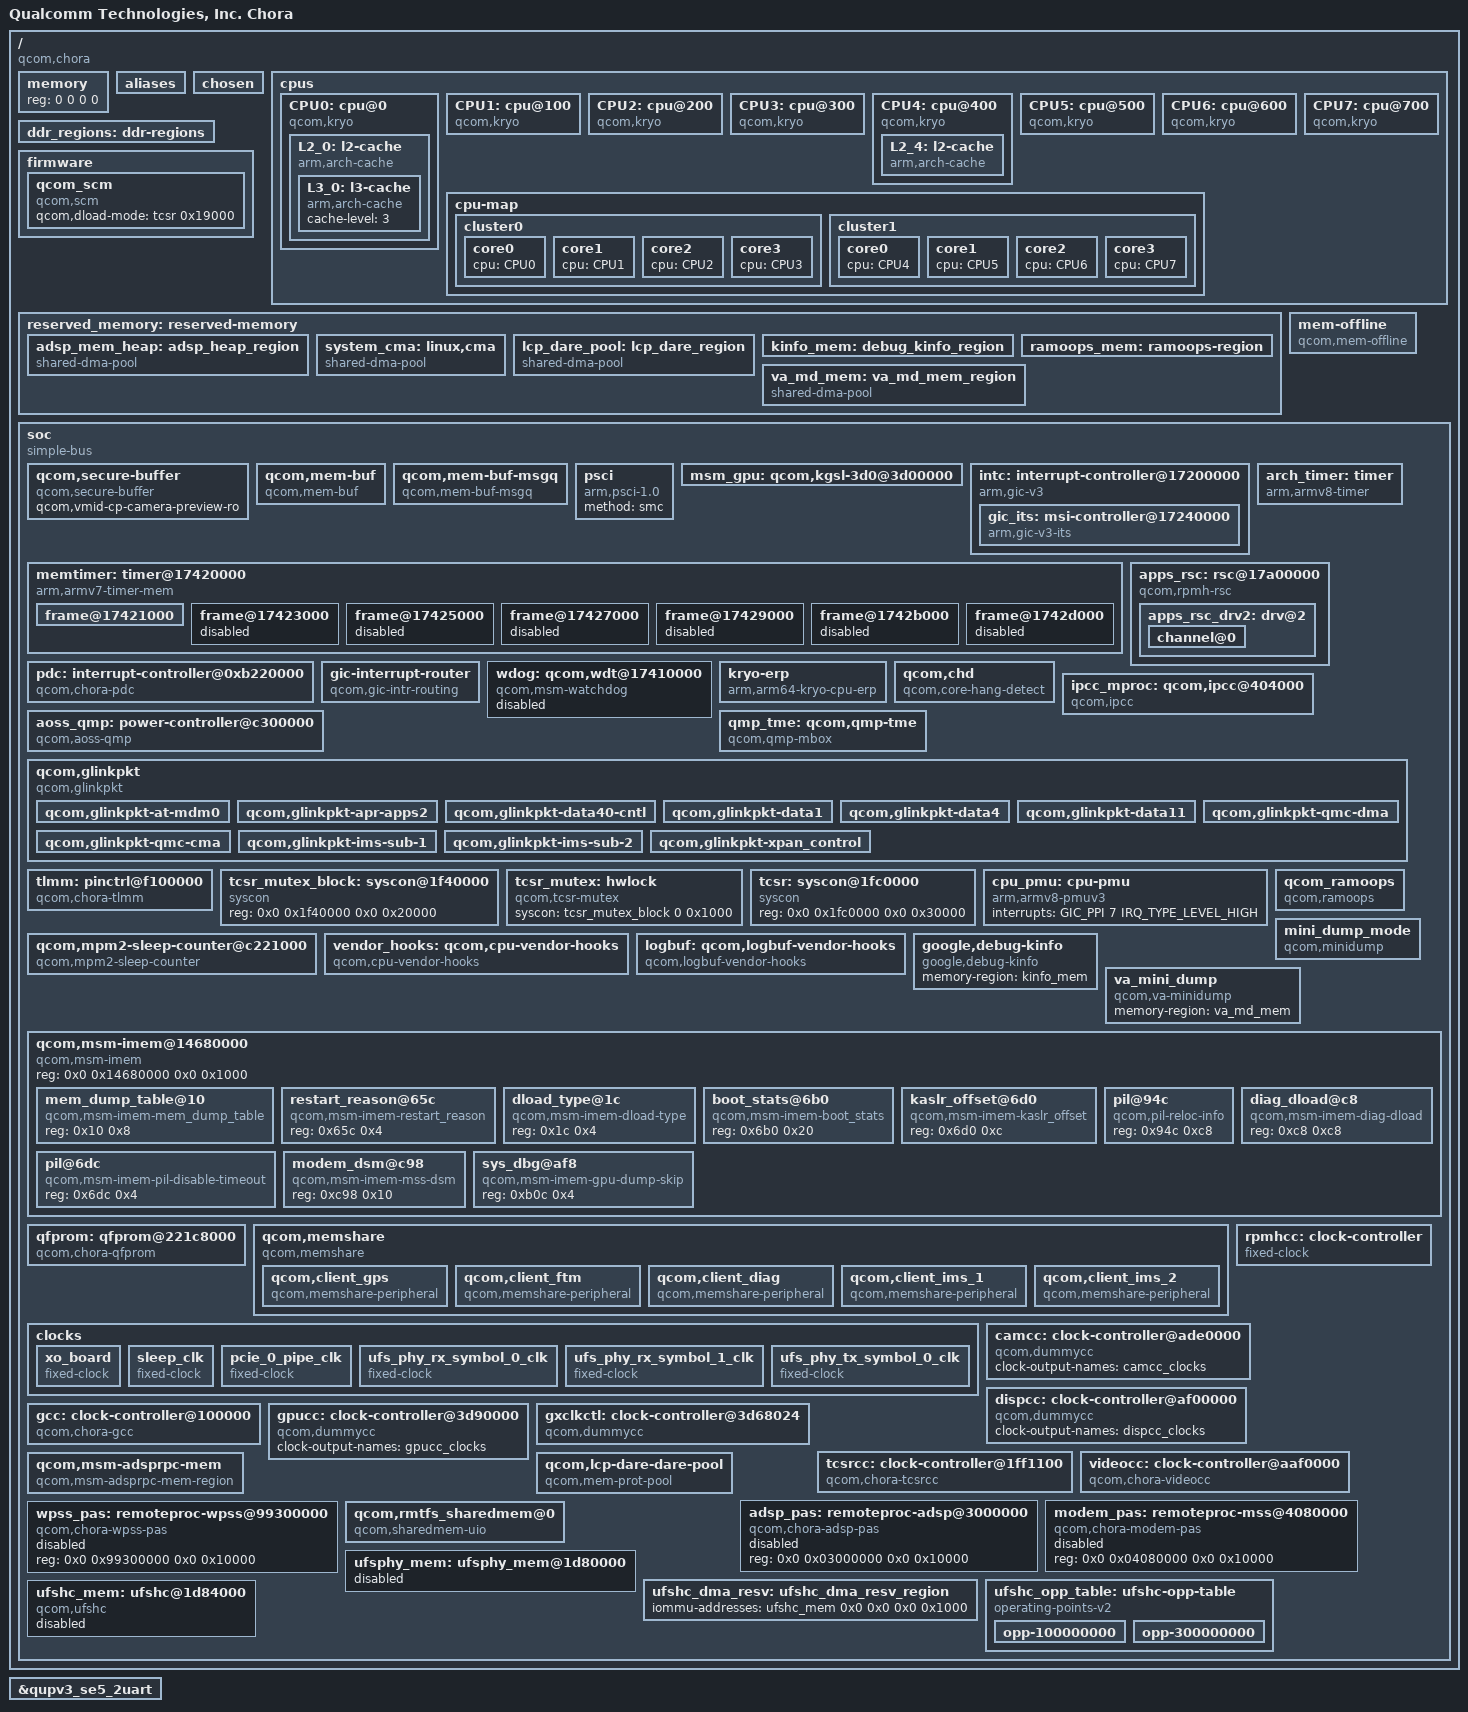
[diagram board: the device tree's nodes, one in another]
// SPDX-License-Identifier: BSD-3-Clause
/*
 * Copyright (c) Qualcomm Technologies, Inc. and/or its subsidiaries.
 */

#include <dt-bindings/clock/qcom,chora-camcc.h>
#include <dt-bindings/clock/qcom,chora-dispcc.h>
#include <dt-bindings/clock/qcom,chora-gcc.h>
#include <dt-bindings/clock/qcom,chora-gpucc.h>
#include <dt-bindings/clock/qcom,chora-tcsrcc.h>
#include <dt-bindings/clock/qcom,chora-videocc.h>
#include <dt-bindings/clock/qcom,rpmh.h>
#include <dt-bindings/interrupt-controller/arm-gic.h>
#include <dt-bindings/soc/qcom,ipcc.h>
#include <dt-bindings/mailbox/qcom-ipcc-canoe.h>
#include <dt-bindings/gpio/gpio.h>
#include <dt-bindings/soc/qcom,rpmh-rsc.h>

/ {
	model = "Qualcomm Technologies, Inc. Chora";
	compatible = "qcom,chora";
	qcom,msm-id = <724 0x10000>;
	interrupt-parent = <&intc>;

	#address-cells = <2>;
	#size-cells = <2>;
	memory { device_type = "memory"; reg = <0 0 0 0>; };

	aliases {
		serial0 = &qupv3_se5_2uart;
		ufshc1 = &ufshc_mem; /* Embedded UFS Slot */
	};

	chosen: chosen {
		bootargs = "loglevel=6 log_buf_len=512K earlycon arm64.nosme arm64.nomte cpufreq.default_governor=performance no-steal-acc kpti=0 swiotlb=0 loop.max_part=7 irqaffinity=0-4 fw_devlink.strict=1 kasan=off rcupdate.rcu_expedited=1 rcu_nocbs=0-7 cgroup_disable=pressure cgroup.memory=nokmem,nosocket disable_dma32=on page_poison=on printk.console_no_auto_verbose=1 sysctl.kernel.panic_on_rcu_stall=1 ftrace_dump_on_oops restrict_cma_redirect=false slub_debug=-";
		stdout-path = "serial0:115200n8";
	};

	cpus {
		#address-cells = <2>;
		#size-cells = <0>;

		CPU0: cpu@0 {
			device_type = "cpu";
			compatible = "qcom,kryo";
			reg = <0x0 0x0>;
			enable-method = "psci";
			next-level-cache = <&L2_0>;
			capacity-dmips-mhz = <1024>;
			dynamic-power-coefficient = <100>;

			L2_0: l2-cache {
				compatible = "arm,arch-cache";
				cache-level = <2>;
				next-level-cache = <&L3_0>;

				L3_0: l3-cache {
					compatible = "arm,arch-cache";
					cache-level = <3>;
				};
			};
		};

		CPU1: cpu@100 {
			device_type = "cpu";
			compatible = "qcom,kryo";
			reg = <0x0 0x100>;
			enable-method = "psci";
			next-level-cache = <&L2_0>;
			capacity-dmips-mhz = <1024>;
			dynamic-power-coefficient = <100>;
		};

		CPU2: cpu@200 {
			device_type = "cpu";
			compatible = "qcom,kryo";
			reg = <0x0 0x200>;
			enable-method = "psci";
			next-level-cache = <&L2_0>;
			capacity-dmips-mhz = <1024>;
			dynamic-power-coefficient = <100>;
		};

		CPU3: cpu@300 {
			device_type = "cpu";
			compatible = "qcom,kryo";
			reg = <0x0 0x300>;
			enable-method = "psci";
			next-level-cache = <&L2_0>;
			capacity-dmips-mhz = <1024>;
			dynamic-power-coefficient = <100>;
		};

		CPU4: cpu@400 {
			device_type = "cpu";
			compatible = "qcom,kryo";
			reg = <0x0 0x400>;
			enable-method = "psci";
			next-level-cache = <&L2_4>;
			capacity-dmips-mhz = <1864>;
			dynamic-power-coefficient = <471>;

			L2_4: l2-cache {
				compatible = "arm,arch-cache";
				cache-level = <2>;
				next-level-cache = <&L3_0>;
			};
		};

		CPU5: cpu@500 {
			device_type = "cpu";
			compatible = "qcom,kryo";
			reg = <0x0 0x500>;
			enable-method = "psci";
			next-level-cache = <&L2_4>;
			capacity-dmips-mhz = <1864>;
			dynamic-power-coefficient = <471>;
		};

		CPU6: cpu@600 {
			device_type = "cpu";
			compatible = "qcom,kryo";
			reg = <0x0 0x600>;
			enable-method = "psci";
			next-level-cache = <&L2_4>;
			capacity-dmips-mhz = <1864>;
			dynamic-power-coefficient = <471>;
		};

		CPU7: cpu@700 {
			device_type = "cpu";
			compatible = "qcom,kryo";
			reg = <0x0 0x700>;
			enable-method = "psci";
			next-level-cache = <&L2_4>;
			capacity-dmips-mhz = <1864>;
			dynamic-power-coefficient = <471>;
		};

		cpu-map {

			cluster0 {

				core0 {
					cpu = <&CPU0>;
				};

				core1 {
					cpu = <&CPU1>;
				};

				core2 {
					cpu = <&CPU2>;
				};

				core3 {
					cpu = <&CPU3>;
				};
			};

			cluster1 {

				core0 {
					cpu = <&CPU4>;
				};

				core1 {
					cpu = <&CPU5>;
				};

				core2 {
					cpu = <&CPU6>;
				};

				core3 {
					cpu = <&CPU7>;
				};
			};
		};
	};

	ddr_regions: ddr-regions { };

	firmware: firmware { };

	reserved_memory: reserved-memory { };

	mem-offline {
		compatible = "qcom,mem-offline";
		offline-sizes = <0x2 0xc0000000 0x1 0x0>;
		granule = <512>;
		qcom,qmp = <&aoss_qmp>;
	};

	soc: soc { };
};

&firmware {
	qcom_scm: qcom_scm {
		compatible = "qcom,scm";
		qcom,dload-mode = <&tcsr 0x19000>;
	};
};

#include "chora-reserved-memory.dtsi"
#include "msm-arm-smmu-chora.dtsi"
#include "chora-dma-heaps.dtsi"

&reserved_memory {
	#address-cells = <2>;
	#size-cells = <2>;
	ranges;

	adsp_mem_heap: adsp_heap_region {
		compatible = "shared-dma-pool";
		alloc-ranges = <0x0 0x00000000 0x0 0xffffffff>;
		reusable;
		alignment = <0x0 0x400000>;
		size = <0x0 0xC00000>;
	};

	/* global autoconfigured region for contiguous allocations */
	system_cma: linux,cma {
		compatible = "shared-dma-pool";
		alloc-ranges = <0x0 0x00000000 0x0 0xffffffff>;
		reusable;
		alignment = <0x0 0x400000>;
		size = <0x0 0x2400000>;
		linux,cma-default;
	};

	lcp_dare_pool: lcp_dare_region {
		compatible = "shared-dma-pool";
		reg = <0x8 0x80000000 0x0 0x6000000>;
		reusable;
		alignment = <0x0 0x400000>;
	};

	kinfo_mem: debug_kinfo_region {
		alloc-ranges = <0x0 0x00000000 0xffffffff 0xffffffff>;
		size = <0x0 0x1000>;
		no-map;
	};

	ramoops_mem: ramoops-region {
		alloc-ranges = <0x1 0x00000000 0xfffffffe 0xffffffff>;
		size = <0x0 0x200000>;
		no-map;
	};

	va_md_mem: va_md_mem_region {
		compatible = "shared-dma-pool";
		alloc-ranges = <0x0 0x00000000 0x0 0xffffffff>;
		reusable;
		size = <0 0x1000000>;
	};
};

&soc {
	#address-cells = <2>;
	#size-cells = <2>;
	ranges = <0 0 0 0 0x10 0>;
	compatible = "simple-bus";

	qcom,secure-buffer {
		compatible = "qcom,secure-buffer";
		qcom,vmid-cp-camera-preview-ro;
	};

	qcom,mem-buf {
		compatible = "qcom,mem-buf";
		qcom,mem-buf-capabilities = "supplier";
		qcom,vmid = <3>;
	};

	qcom,mem-buf-msgq {
		compatible = "qcom,mem-buf-msgq";
	};

	psci: psci {
		compatible = "arm,psci-1.0";
		method = "smc";
	};

	msm_gpu: qcom,kgsl-3d0@3d00000 { };

	intc: interrupt-controller@17200000 {
		compatible = "arm,gic-v3";
		#interrupt-cells = <3>;
		interrupt-controller;
		#redistributor-regions = <1>;
		redistributor-stride = <0x0 0x20000>;
		reg = <0x0 0x17200000 0x0 0x10000>,	/* GICD */
		      <0x0 0x17260000 0x0 0x100000>;	/* GICR * 8 */
		interrupts = <GIC_PPI 9 IRQ_TYPE_LEVEL_LOW>;

		#address-cells = <1>;
		#size-cells = <1>;
		ranges;
		gic_its: msi-controller@17240000 {
			compatible = "arm,gic-v3-its";
			msi-controller;
			#msi-cells = <1>;
			reg = <0x17240000 0x20000>;
		};
	};

	arch_timer: timer {
		compatible = "arm,armv8-timer";
		interrupts = <GIC_PPI 13 (GIC_CPU_MASK_SIMPLE(8) | IRQ_TYPE_LEVEL_LOW)>,
			     <GIC_PPI 14 (GIC_CPU_MASK_SIMPLE(8) | IRQ_TYPE_LEVEL_LOW)>,
			     <GIC_PPI 11 (GIC_CPU_MASK_SIMPLE(8) | IRQ_TYPE_LEVEL_LOW)>,
			     <GIC_PPI 10 (GIC_CPU_MASK_SIMPLE(8) | IRQ_TYPE_LEVEL_LOW)>;
		clock-frequency = <19200000>;
	};

	memtimer: timer@17420000 {
		compatible = "arm,armv7-timer-mem";
		reg = <0x0 0x17420000 0x0 0x1000>;
		clock-frequency = <19200000>;

		#address-cells = <1>;
		#size-cells = <1>;
		ranges;
		frame@17421000 {
			frame-number = <0>;
			interrupts = <GIC_SPI 8 IRQ_TYPE_LEVEL_HIGH>,
				     <GIC_SPI 6 IRQ_TYPE_LEVEL_HIGH>;
			reg = <0x17421000 0x1000>,
			      <0x17422000 0x1000>;
		};

		frame@17423000 {
			frame-number = <1>;
			interrupts = <GIC_SPI 9 IRQ_TYPE_LEVEL_HIGH>;
			reg = <0x17423000 0x1000>;
			status = "disabled";
		};

		frame@17425000 {
			frame-number = <2>;
			interrupts = <GIC_SPI 10 IRQ_TYPE_LEVEL_HIGH>;
			reg = <0x17425000 0x1000>;
			status = "disabled";
		};

		frame@17427000 {
			frame-number = <3>;
			interrupts = <GIC_SPI 11 IRQ_TYPE_LEVEL_HIGH>;
			reg = <0x17427000 0x1000>;
			status = "disabled";
		};

		frame@17429000 {
			frame-number = <4>;
			interrupts = <GIC_SPI 12 IRQ_TYPE_LEVEL_HIGH>;
			reg = <0x17429000 0x1000>;
			status = "disabled";
		};

		frame@1742b000 {
			frame-number = <5>;
			interrupts = <GIC_SPI 13 IRQ_TYPE_LEVEL_HIGH>;
			reg = <0x1742b000 0x1000>;
			status = "disabled";
		};

		frame@1742d000 {
			frame-number = <6>;
			interrupts = <GIC_SPI 14 IRQ_TYPE_LEVEL_HIGH>;
			reg = <0x1742d000 0x1000>;
			status = "disabled";
		};
	};

	apps_rsc: rsc@17a00000 {
		label = "apps_rsc";
		compatible = "qcom,rpmh-rsc";
		reg = <0x17a00000 0x10000>,
		      <0x17a10000 0x10000>,
		      <0x17a20000 0x10000>;
		reg-names = "drv-0", "drv-1", "drv-2";
		qcom,drv-count = <3>;
		interrupts = <GIC_SPI 3 IRQ_TYPE_LEVEL_HIGH>,
			     <GIC_SPI 4 IRQ_TYPE_LEVEL_HIGH>,
			     <GIC_SPI 5 IRQ_TYPE_LEVEL_HIGH>;

		apps_rsc_drv2: drv@2 {
			qcom,drv-id = <2>;
			qcom,tcs-offset = <0xd00>;
			qcom,tcs-distance = <0x2a0>;

			channel@0 {
				 qcom,tcs-config = <ACTIVE_TCS    3>,
						   <SLEEP_TCS     2>,
						   <WAKE_TCS      2>,
						   <CONTROL_TCS   0>,
						   <FAST_PATH_TCS 1>;
			};
		};
	};

	pdc: interrupt-controller@0xb220000 {
		compatible = "qcom,chora-pdc", "qcom,pdc";
		reg = <0xb220000 0x10000>, <0x174000f0 0x64>;
		qcom,pdc-ranges = <0 480 40>, <40 140 11>, <51 527 47>,
				  <98 609 31>, <129 63 1>, <130 716 12>,
				  <142 251 5>;
		#interrupt-cells = <2>;
		interrupt-parent = <&intc>;
		interrupt-controller;
	};

	gic-interrupt-router {
		compatible = "qcom,gic-intr-routing";
		/* keep few silver cores in class0 only to avoid wakeup of gold cores */
		qcom,gic-class0-cpus = <&CPU0 &CPU1 &CPU2 &CPU3>;
		/* keep gold cores in class1 */
		qcom,gic-class1-cpus = <&CPU4 &CPU5 &CPU6 &CPU7>;
		qcom,gic-cpulist = <&CPU0 &CPU1 &CPU2 &CPU3 &CPU4 &CPU5 &CPU6 &CPU7>;
		qcom,gic-runtime-cpu-class-en;
	};

	wdog: qcom,wdt@17410000 {
		compatible = "qcom,msm-watchdog";
		reg = <0x0 0x17410000 0x0 0x1000>;
		reg-names = "wdt-base";
		interrupts = <GIC_SPI 0 IRQ_TYPE_LEVEL_HIGH>,
			     <GIC_SPI 1 IRQ_TYPE_LEVEL_HIGH>;
		qcom,bark-time = <11000>;
		qcom,pet-time = <9360>;
		qcom,ipi-ping;
		qcom,wakeup-enable;

		status = "disabled";
	};

	kryo-erp {
		compatible = "arm,arm64-kryo-cpu-erp";
		interrupts = <GIC_PPI 0 IRQ_TYPE_LEVEL_HIGH>,
			<GIC_SPI 35 IRQ_TYPE_LEVEL_HIGH>;
		interrupt-names = "l1-l2-faultirq","l3-scu-faultirq";
	};

	qcom,chd {
		compatible = "qcom,core-hang-detect";
		label = "core";
		qcom,threshold-arr = <0x17800058 0x17810058 0x17820058 0x17830058
			0x17840058 0x17850058 0x17860058 0x17870058>;
		qcom,config-arr = <0x17800060 0x17810060 0x17820060 0x17830060
			0x17840060 0x17850060 0x17860060 0x17870060>;
	};

	ipcc_mproc: qcom,ipcc@404000 {
		compatible = "qcom,ipcc";
		reg = <0x0 0x404000 0x0 0x1000>;
		interrupts = <GIC_SPI 256 IRQ_TYPE_LEVEL_HIGH>;
		interrupt-controller;
		#interrupt-cells = <3>;
		#mbox-cells = <2>;
	};


	aoss_qmp: power-controller@c300000 {
		compatible = "qcom,aoss-qmp";
		reg = <0xc300000 0x400>;
		interrupt-parent = <&ipcc_mproc>;
		interrupts = <IPCC_MPROC_AOP
			      IPCC_MPROC_SIGNAL_GLINK_QMP
			      IRQ_TYPE_EDGE_RISING>;
		mboxes = <&ipcc_mproc IPCC_MPROC_AOP
			  IPCC_MPROC_SIGNAL_GLINK_QMP>;

		#power-domain-cells = <1>;
		#clock-cells = <0>;
	};

	qmp_tme: qcom,qmp-tme {
		compatible = "qcom,qmp-mbox";
		qcom,remote-pid = <14>;
		mboxes = <&ipcc_mproc IPCC_MPROC_TME
			  IPCC_MPROC_SIGNAL_GLINK_QMP>;
		mbox-names = "tme_qmp";
		interrupt-parent = <&ipcc_mproc>;
		interrupts = <IPCC_MPROC_TME
			      IPCC_MPROC_SIGNAL_GLINK_QMP
			      IRQ_TYPE_EDGE_RISING>;

		label = "tme";
		qcom,early-boot;
		priority = <0>;
		mbox-desc-offset = <0x0>;
		#mbox-cells = <1>;
	};

	qcom,glinkpkt {
		compatible = "qcom,glinkpkt";

		qcom,glinkpkt-at-mdm0 {
			qcom,glinkpkt-edge = "mpss";
			qcom,glinkpkt-ch-name = "DS";
			qcom,glinkpkt-dev-name = "at_mdm0";
		};

		qcom,glinkpkt-apr-apps2 {
			qcom,glinkpkt-edge = "adsp";
			qcom,glinkpkt-ch-name = "apr_apps2";
			qcom,glinkpkt-dev-name = "apr_apps2";
		};

		qcom,glinkpkt-data40-cntl {
			qcom,glinkpkt-edge = "mpss";
			qcom,glinkpkt-ch-name = "DATA40_CNTL";
			qcom,glinkpkt-dev-name = "smdcntl8";
		};

		qcom,glinkpkt-data1 {
			qcom,glinkpkt-edge = "mpss";
			qcom,glinkpkt-ch-name = "DATA1";
			qcom,glinkpkt-dev-name = "smd7";
		};

		qcom,glinkpkt-data4 {
			qcom,glinkpkt-edge = "mpss";
			qcom,glinkpkt-ch-name = "DATA4";
			qcom,glinkpkt-dev-name = "smd8";
		};

		qcom,glinkpkt-data11 {
			qcom,glinkpkt-edge = "mpss";
			qcom,glinkpkt-ch-name = "DATA11";
			qcom,glinkpkt-dev-name = "smd11";
		};

		qcom,glinkpkt-qmc-dma {
			qcom,glinkpkt-edge = "mpss";
			qcom,glinkpkt-ch-name = "QMC_DMA_LINE";
			qcom,glinkpkt-dev-name = "qmc_dma";
			qcom,glinkpkt-enable-ch-close;
		};

		qcom,glinkpkt-qmc-cma {
			qcom,glinkpkt-edge = "mpss";
			qcom,glinkpkt-ch-name = "QMC_CMA_LINE";
			qcom,glinkpkt-dev-name = "qmc_cma";
			qcom,glinkpkt-enable-ch-close;
		};

		qcom,glinkpkt-ims-sub-1 {
			qcom,glinkpkt-edge = "mpss";
			qcom,glinkpkt-ch-name = "Ims_dc_sub1";
			qcom,glinkpkt-dev-name = "ims_dc_sub1";
			qcom,glinkpkt-enable-ch-close;
		};

		qcom,glinkpkt-ims-sub-2 {
			qcom,glinkpkt-edge = "mpss";
			qcom,glinkpkt-ch-name = "Ims_dc_sub2";
			qcom,glinkpkt-dev-name = "ims_dc_sub2";
			qcom,glinkpkt-enable-ch-close;
		};

		qcom,glinkpkt-xpan_control {
			qcom,glinkpkt-edge = "adsp";
			qcom,glinkpkt-ch-name = "bt_cp_ctrl";
			qcom,glinkpkt-dev-name = "bt_cp_ctrl";
		};
	};

	tlmm: pinctrl@f100000 {
		compatible = "qcom,chora-tlmm";
		reg = <0x0 0xf100000 0x0 0xf00000>;
		gpio-controller;
		#gpio-cells = <2>;
		interrupt-controller;
		#interrupt-cells = <2>;
		interrupts = <GIC_SPI 208 IRQ_TYPE_LEVEL_HIGH>;
		qcom,gpios-reserved = <63>;
	};

	tcsr_mutex_block: syscon@1f40000 {
		compatible = "syscon";
		reg = <0x0 0x1f40000 0x0 0x20000>;
	};

	tcsr_mutex: hwlock {
		compatible = "qcom,tcsr-mutex";
		syscon = <&tcsr_mutex_block 0 0x1000>;
		#hwlock-cells = <1>;
	};

	tcsr: syscon@1fc0000 {
		compatible = "syscon";
		reg = <0x0 0x1fc0000 0x0 0x30000>;
	};

	cpu_pmu: cpu-pmu {
		compatible = "arm,armv8-pmuv3";
		interrupts = <GIC_PPI 7 IRQ_TYPE_LEVEL_HIGH>;
	};

	qcom,mpm2-sleep-counter@c221000 {
		compatible = "qcom,mpm2-sleep-counter";
		reg = <0x0 0xc221000 0x0 0x1000>;
		clock-frequency = <32768>;
	};

	vendor_hooks: qcom,cpu-vendor-hooks {
		compatible = "qcom,cpu-vendor-hooks";
	};

	logbuf: qcom,logbuf-vendor-hooks {
		compatible = "qcom,logbuf-vendor-hooks";
	};

	google,debug-kinfo {
		compatible = "google,debug-kinfo";
		memory-region = <&kinfo_mem>;
	};

	qcom_ramoops {
		compatible = "qcom,ramoops";
		memory-region = <&ramoops_mem>;
		pmsg-size = <0x200000>;
		mem-type = <2>;
	};

	mini_dump_mode {
		compatible = "qcom,minidump";
	};

	va_mini_dump {
		compatible = "qcom,va-minidump";
		memory-region = <&va_md_mem>;
	};

	qcom,msm-imem@14680000 {
		compatible = "qcom,msm-imem";
		reg = <0x0 0x14680000 0x0 0x1000>;
		ranges = <0x0 0x0 0x14680000 0x1000>;
		#address-cells = <1>;
		#size-cells = <1>;

		mem_dump_table@10 {
			compatible = "qcom,msm-imem-mem_dump_table";
			reg = <0x10 0x8>;
		};

		restart_reason@65c {
			compatible = "qcom,msm-imem-restart_reason";
			reg = <0x65c 0x4>;
		};

		dload_type@1c {
			compatible = "qcom,msm-imem-dload-type";
			reg = <0x1c 0x4>;
		};

		boot_stats@6b0 {
			compatible = "qcom,msm-imem-boot_stats";
			reg = <0x6b0 0x20>;
		};

		kaslr_offset@6d0 {
			compatible = "qcom,msm-imem-kaslr_offset";
			reg = <0x6d0 0xc>;
		};

		pil@94c {
			compatible = "qcom,pil-reloc-info";
			reg = <0x94c 0xc8>;
		};

		pil@6dc {
			compatible = "qcom,msm-imem-pil-disable-timeout";
			reg = <0x6dc 0x4>;
		};

		diag_dload@c8 {
			compatible = "qcom,msm-imem-diag-dload";
			reg = <0xc8 0xc8>;
		};

		modem_dsm@c98 {
			compatible = "qcom,msm-imem-mss-dsm";
			reg = <0xc98 0x10>;
		};

		sys_dbg@af8 {
			compatible = "qcom,msm-imem-gpu-dump-skip";
			reg = <0xb0c 0x4>;
		};
	};

	qfprom: qfprom@221c8000 {
		compatible = "qcom,chora-qfprom", "qcom,qfprom";
		reg = <0x0 0x221c8000 0x0 0x1000>;
		#address-cells = <1>;
		#size-cells = <1>;
		read-only;
		ranges;
	};

	qcom,memshare {
		compatible = "qcom,memshare";

		qcom,client_gps {
			compatible = "qcom,memshare-peripheral";
			client_name = "gps";
			qcom,peripheral-size = <0x0>;
			qcom,client-id = <0>;
			qcom,allocate-boot-time;
			label = "modem";
		};

		qcom,client_ftm {
			compatible = "qcom,memshare-peripheral";
			client_name = "ftm";
			qcom,peripheral-size = <0x0>;
			qcom,client-id = <2>;
			label = "modem";
		};

		qcom,client_diag {
			compatible = "qcom,memshare-peripheral";
			client_name = "diag";
			qcom,peripheral-size = <0x500000>;
			qcom,client-id = <1>;
			qcom,allocate-on-request;
			label = "modem";
		};

		qcom,client_ims_1 {
			compatible = "qcom,memshare-peripheral";
			client_name = "ims_1";
			qcom,peripheral-size = <0x100000>;
			qcom,client-id = <7>;
			qcom,allocate-on-request;
			qcom,shared;
			label = "modem";
		};

		qcom,client_ims_2 {
			compatible = "qcom,memshare-peripheral";
			client_name = "ims_2";
			qcom,peripheral-size = <0x100000>;
			qcom,client-id = <8>;
			qcom,allocate-on-request;
			qcom,shared;
			label = "modem";
		};
	};

	clocks {
		xo_board: xo_board {
			compatible = "fixed-clock";
			clock-frequency = <76800000>;
			clock-output-names = "xo_board";
			#clock-cells = <0>;
		};

		sleep_clk: sleep_clk {
			compatible = "fixed-clock";
			clock-frequency = <32000>;
			clock-output-names = "sleep_clk";
			#clock-cells = <0>;
		};

		pcie_0_pipe_clk: pcie_0_pipe_clk {
			compatible = "fixed-clock";
			clock-frequency = <1000>;
			clock-output-names = "pcie_0_pipe_clk";
			#clock-cells = <0>;
		};

		ufs_phy_rx_symbol_0_clk: ufs_phy_rx_symbol_0_clk {
			compatible = "fixed-clock";
			clock-frequency = <1000>;
			clock-output-names = "ufs_phy_rx_symbol_0_clk";
			#clock-cells = <0>;
		};

		ufs_phy_rx_symbol_1_clk: ufs_phy_rx_symbol_1_clk {
			compatible = "fixed-clock";
			clock-frequency = <1000>;
			clock-output-names = "ufs_phy_rx_symbol_1_clk";
			#clock-cells = <0>;
		};

		ufs_phy_tx_symbol_0_clk: ufs_phy_tx_symbol_0_clk {
			compatible = "fixed-clock";
			clock-frequency = <1000>;
			clock-output-names = "ufs_phy_tx_symbol_0_clk";
			#clock-cells = <0>;
		};
	};

	rpmhcc: clock-controller {
		compatible = "fixed-clock";
		clock-output-names = "rpmh_clocks";
		clock-frequency = <19200000>;
		#clock-cells = <1>;
	};

	camcc: clock-controller@ade0000 {
		compatible = "qcom,dummycc";
		clock-output-names = "camcc_clocks";
		#clock-cells = <1>;
		#reset-cells = <1>;
		#power-domain-cells = <1>;
	};

	dispcc: clock-controller@af00000 {
		compatible = "qcom,dummycc";
		clock-output-names = "dispcc_clocks";
		#clock-cells = <1>;
		#reset-cells = <1>;
		#power-domain-cells = <1>;
	};

	gcc: clock-controller@100000 {
		compatible = "qcom,chora-gcc", "syscon";
		reg = <0x0 0x100000 0x0 0x1f4200>;
		reg-name = "cc_base";
		vdd_cx-supply = <&VDD_CX_LEVEL>;
		vdd_mx-supply = <&VDD_MX_LEVEL>;
		clocks = <&rpmhcc RPMH_CXO_CLK>,
			 <&pcie_0_pipe_clk>,
			 <&sleep_clk>,
			 <&ufs_phy_rx_symbol_0_clk>,
			 <&ufs_phy_rx_symbol_1_clk>,
			 <&ufs_phy_tx_symbol_0_clk>;
		clock-names = "bi_tcxo",
			      "pcie_0_pipe_clk",
			      "sleep_clk",
			      "ufs_phy_rx_symbol_0_clk",
			      "ufs_phy_rx_symbol_1_clk",
			      "ufs_phy_tx_symbol_0_clk";
		#clock-cells = <1>;
		#reset-cells = <1>;
		#power-domain-cells = <1>;
	};

	gpucc: clock-controller@3d90000 {
		compatible = "qcom,dummycc";
		clock-output-names = "gpucc_clocks";
		#clock-cells = <1>;
		#reset-cells = <1>;
		#power-domain-cells = <1>;
	};

	gxclkctl: clock-controller@3d68024 {
		compatible = "qcom,dummycc";
		#power-domain-cells = <1>;
	};

	tcsrcc: clock-controller@1ff1100 {
		compatible = "qcom,chora-tcsrcc", "syscon";
		reg = <0x0 0x1ff1100 0x0 0x20>;
		reg-name = "cc_base";
		#clock-cells = <1>;
		#reset-cells = <1>;
	};

	videocc: clock-controller@aaf0000 {
		compatible = "qcom,chora-videocc", "syscon";
		reg = <0x0 0xaaf0000 0x0 0x10000>;
		reg-name = "cc_base";
		vdd_cx-supply = <&VDD_CX_LEVEL>;
		vdd_mx-supply = <&VDD_MX_LEVEL>;
		clocks = <&rpmhcc RPMH_CXO_CLK>,
			 <&rpmhcc RPMH_CXO_CLK_A>,
			<&gcc GCC_VIDEO_AHB_CLK>,
			<&sleep_clk>;
		clock-names = "bi_tcxo",
				"bi_tcxo_ao",
				"iface",
				"sleep_clk";
		#clock-cells = <1>;
		#reset-cells = <1>;
		#power-domain-cells = <1>;
	};

	qcom,msm-adsprpc-mem {
		compatible = "qcom,msm-adsprpc-mem-region";
		memory-region = <&adsp_mem_heap>;
		restrict-access;
	};

	qcom,lcp-dare-dare-pool {
		compatible = "qcom,mem-prot-pool";
		memory-region = <&lcp_dare_pool>;
		qcom,lcp-dare;
	};

	adsp_pas: remoteproc-adsp@3000000 {
		compatible = "qcom,chora-adsp-pas";
		reg = <0x0 0x03000000 0x0 0x10000>;

		status = "disabled";
	};

	modem_pas: remoteproc-mss@4080000 {
		compatible = "qcom,chora-modem-pas";
		reg = <0x0 0x04080000 0x0 0x10000>;

		status = "disabled";
	};

	wpss_pas: remoteproc-wpss@99300000 {
		compatible = "qcom,chora-wpss-pas";
		reg = <0x0 0x99300000 0x0 0x10000>;

		status = "disabled";
	};

	qcom,rmtfs_sharedmem@0 {
		compatible = "qcom,sharedmem-uio";
		reg = <0x0 0x0 0x0 0x280000>;
		reg-names = "rmtfs";
		qcom,client-id = <0x00000001>;
	};

	ufsphy_mem: ufsphy_mem@1d80000 {
		#address-cells = <2>;
		#size-cells = <2>;
		reg = <0x0 0x1d80000 0x0 0x2000>;
		reg-names = "phy_mem";
		#phy-cells = <0>;

		power-domains = <&gcc GCC_UFS_MEM_PHY_GDSC>;
		lanes-per-direction = <2>;
		clock-names = "ref_clk_src",
			"ref_aux_clk", "qref_clk",
			"rx_sym0_mux_clk", "rx_sym1_mux_clk", "tx_sym0_mux_clk",
			"rx_sym0_phy_clk", "rx_sym1_phy_clk", "tx_sym0_phy_clk";
		clocks = <&rpmhcc RPMH_CXO_CLK>,
			<&gcc GCC_UFS_PHY_PHY_AUX_CLK>,
			<&tcsrcc TCSR_UFS_PHY_CLKREF_EN>,
			<&gcc GCC_UFS_PHY_RX_SYMBOL_0_CLK_SRC>,
			<&gcc GCC_UFS_PHY_RX_SYMBOL_1_CLK_SRC>,
			<&gcc GCC_UFS_PHY_TX_SYMBOL_0_CLK_SRC>,
			<&ufs_phy_rx_symbol_0_clk>,
			<&ufs_phy_rx_symbol_1_clk>,
			<&ufs_phy_tx_symbol_0_clk>;
		resets = <&ufshc_mem 0>;
		status = "disabled";
	};

	ufshc_dma_resv: ufshc_dma_resv_region {
		/*
		 * Restrict IOVA mappings for UFSHC buffers to the 3 GB region
		 * from 0x1000 - 0xffffffff.
		 */
		iommu-addresses = <&ufshc_mem 0x0 0x0 0x0 0x1000>;
	};

	ufshc_opp_table: ufshc-opp-table {
		compatible = "operating-points-v2";

		// LOW_SVS
		opp-100000000 {
			opp-hz = /bits/ 64 <75000000>,
				 /bits/ 64 <0>,
				 /bits/ 64 <0>,
				 /bits/ 64 <75000000>,
				 /bits/ 64 <100000000>,
				 /bits/ 64 <0>,
				 /bits/ 64 <0>,
				 /bits/ 64 <0>,
				 /bits/ 64 <0>;
		};

		// NOM/TURBO
		opp-300000000 {
			opp-hz = /bits/ 64 <300000000>,
				 /bits/ 64 <0>,
				 /bits/ 64 <0>,
				 /bits/ 64 <300000000>,
				 /bits/ 64 <403000000>,
				 /bits/ 64 <0>,
				 /bits/ 64 <0>,
				 /bits/ 64 <0>,
				 /bits/ 64 <0>;
		};
	};

	ufshc_mem: ufshc@1d84000 {
		compatible = "qcom,ufshc";
		reg = <0x0 0x1d84000 0x0 0x3000>;
		reg-names = "ufs_mem";
		interrupts = <GIC_SPI 265 IRQ_TYPE_LEVEL_HIGH>;
		phys = <&ufsphy_mem>;
		phy-names = "ufsphy";
		#reset-cells = <1>;

		power-domains = <&gcc GCC_UFS_PHY_GDSC>;
		lanes-per-direction = <2>;
		clock-names =
			"core_clk",
			"bus_aggr_clk",
			"iface_clk",
			"core_clk_unipro",
			"core_clk_ice",
			"ref_clk",
			"tx_lane0_sync_clk",
			"rx_lane0_sync_clk",
			"rx_lane1_sync_clk";
		clocks =
			<&gcc GCC_UFS_PHY_AXI_CLK>,
			<&gcc GCC_AGGRE_UFS_PHY_AXI_CLK>,
			<&gcc GCC_UFS_PHY_AHB_CLK>,
			<&gcc GCC_UFS_PHY_UNIPRO_CORE_CLK>,
			<&gcc GCC_UFS_PHY_ICE_CORE_CLK>,
			<&rpmhcc RPMH_CXO_CLK>,
			<&gcc GCC_UFS_PHY_TX_SYMBOL_0_CLK>,
			<&gcc GCC_UFS_PHY_RX_SYMBOL_0_CLK>,
			<&gcc GCC_UFS_PHY_RX_SYMBOL_1_CLK>;

		/* set the dependency that smmu being probed before ufs */
		depends-on-supply = <&apps_smmu>;

		iommus = <&apps_smmu 0x60 0x0>;
		qcom,iommu-dma = "fastmap";
		dma-coherent;

		qcom,max-cpus = <8>;

		reset-gpios = <&tlmm 217 GPIO_ACTIVE_LOW>;
		resets = <&gcc GCC_UFS_PHY_BCR>;
		reset-names = "rst";

		status = "disabled";
	};
};

#include "chora-pinctrl.dtsi"
#include "chora-stub-regulators.dtsi"
#include "chora-qupv3.dtsi"
#include "chora-usb.dtsi"

&qupv3_se5_2uart {
	status = "ok";
};
